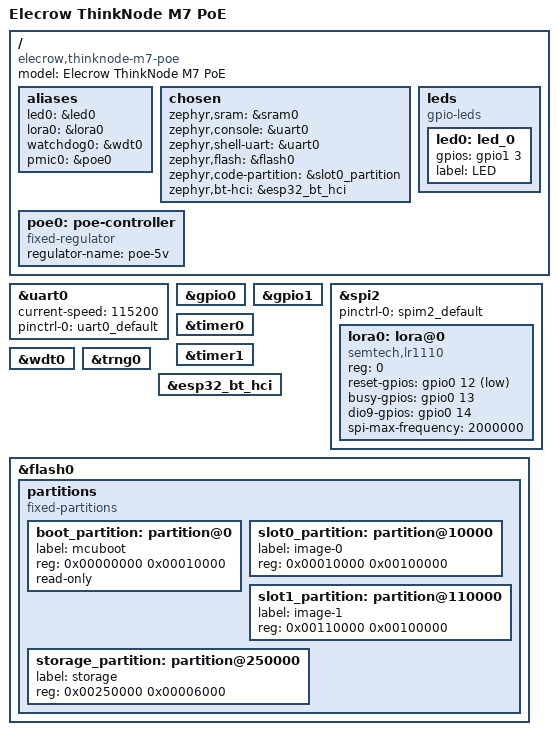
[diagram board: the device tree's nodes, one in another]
/*
 * SPDX-License-Identifier: GPL-3.0-or-later
 * SPDX-FileCopyrightText: The contributors to the LICHEN project
 *
 * Elecrow ThinkNode M7 PoE — ESP32-S3 + LR1110 + SI3402 PoE PD (PG on GPIO21). Ethernet RMII/PHY (LAN8720?) uncertain; WiFi preferred for border-router per spec. See HUMAN bead project-LICHEN-500k for pinout confirmation.
 *
 * Pin mapping (Meshtastic cross-check + schematics): LR1110 SPI2 SCK=9/MOSI=10/MISO=11/CS=8, RESET=12, BUSY=13, DIO9=14. PoE power-good GPIO21. Update for Kconfig_LICHEN_POE.
 */
 /dts-v1/;

#include <espressif/esp32s3/esp32s3_fn8.dtsi>
#include "thinknode_m7-pinctrl.dtsi"
#include <zephyr/dt-bindings/lora/sx126x.h>
#include <zephyr/dt-bindings/input/input-event-codes.h>

 / {
	model = "Elecrow ThinkNode M7 PoE";
	compatible = "elecrow,thinknode-m7-poe";

	aliases {
		led0      = &led0;
		lora0     = &lora0;
		watchdog0 = &wdt0;
		pmic0     = &poe0;
	};

	chosen {
		zephyr,sram           = &sram0;
		zephyr,console        = &uart0;
		zephyr,shell-uart     = &uart0;
		zephyr,flash          = &flash0;
		zephyr,code-partition = &slot0_partition;
		zephyr,bt-hci         = &esp32_bt_hci;
	};

	leds {
		compatible = "gpio-leds";
		led0: led_0 {
			gpios = <&gpio1 3 GPIO_ACTIVE_HIGH>;
			label = "LED";
		};
	};

	poe0: poe-controller {
		compatible = "fixed-regulator"; /* SI3402 identified; placeholder until proper binding */
		status = "okay";
		regulator-name = "poe-5v";
	};
};

&uart0 {
	status = "okay";
	current-speed = <115200>;
	pinctrl-0 = <&uart0_default>;
	pinctrl-names = "default";
};

&gpio0 {
	status = "okay";
};

&gpio1 {
	status = "okay";
};

/*
 * LR1110 on SPI2 (pin mapping identified: SCK=9, MOSI=10, MISO=11, CS=8,
 * RESET=12, BUSY=13, DIO9=14). PoE SI3402 PG on GPIO21.
 */
&spi2 {
	status = "okay";
	pinctrl-0 = <&spim2_default>;
	pinctrl-names = "default";

	lora0: lora@0 {
		compatible = "semtech,lr1110";
		reg = <0>;
		reset-gpios = <&gpio0 12 (GPIO_OPEN_DRAIN | GPIO_ACTIVE_LOW)>;
		busy-gpios  = <&gpio0 13 GPIO_ACTIVE_HIGH>;
		dio9-gpios  = <&gpio0 14 GPIO_ACTIVE_HIGH>;
		spi-max-frequency = <2000000>;
		status = "okay";
	};
};

&timer0 { status = "okay"; };
&timer1 { status = "okay"; };
&wdt0 {
	status = "okay";
};

&trng0 {
	status = "okay";
};

&esp32_bt_hci {
	status = "okay";
};

&flash0 {
	status = "okay";
	partitions {
		compatible = "fixed-partitions";
		#address-cells = <1>;
		#size-cells = <1>;

		boot_partition: partition@0 {
			label = "mcuboot";
			reg = <0x00000000 0x00010000>;
			read-only;
		};
		slot0_partition: partition@10000 {
			label = "image-0";
			reg = <0x00010000 0x00100000>;
		};
		slot1_partition: partition@110000 {
			label = "image-1";
			reg = <0x00110000 0x00100000>;
		};
		storage_partition: partition@250000 {
			label = "storage";
			reg = <0x00250000 0x00006000>;
		};
	};
};

/* PoE and Ethernet support via Kconfig + regulator */
